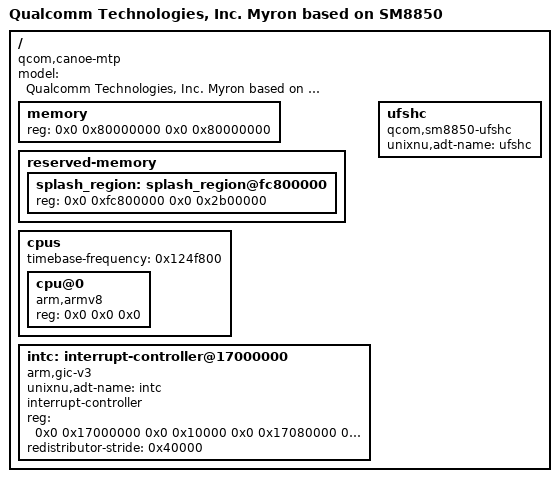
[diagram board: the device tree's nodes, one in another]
// SPDX-License-Identifier: BSD-3-Clause
//
// Redmi K90 Pro Max (myron, SM8850 / Canoe) handoff device tree for UniXNU.
// Generated by work/make_handoff_dts.py -- edit that file, not this one.
//
// This is the curated tree the ADT is built from, not the stock Android DTB
// (dts/myron.dts, kept as the byte-exact address reference). Format 2 exports
// an arm-io child only for a node carrying unixnu,adt-name, so only the nodes
// below reach the kernel.
//
// Values are copied from UniXNU-myron/scripts/make-myron-adt.py, the generator
// that reached SpringBoard on this phone with the iPadOS 17.7.11 image; see the
// docstring of the generator script for where each one came from.

/dts-v1/;

/ {
    model = "Qualcomm Technologies, Inc. Myron based on SM8850";
    compatible = "qcom,canoe-mtp", "qcom,canoe";
    #address-cells = <0x2>;
    #size-cells = <0x2>;

    memory {
        device_type = "memory";
        // First DRAM bank from this unit's boot log; the second
        // (0x880000000 + 0x380000000) is not declared, as upstream.
        reg = <0x0 0x80000000 0x0 0x80000000>;
    };

    // Measured on this unit (myron-observed.json): the ABL splash buffer that
    // the boot image's [[bootimg.dtb_node]] entries address. Values, not guesses.
    reserved-memory {
        #address-cells = <0x2>;
        #size-cells = <0x2>;
        ranges;
        splash_region: splash_region@fc800000 {
            reg = <0x0 0xfc800000 0x0 0x2b00000>;
        };
    };

    cpus {
        #address-cells = <0x2>;
        #size-cells = <0x1>;
        // Copied from the arm,armv8-timer clock-frequency of the stock DTB;
        // XNU reads it from /cpus.
        timebase-frequency = <0x124f800>;
        cpu@0 {
            device_type = "cpu";
            compatible = "arm,armv8";
            reg = <0x0 0x0 0x0>;
        };
    };

    // arm-io child: the ADT name is the child name the kernel looks for.
    intc: interrupt-controller@17000000 {
        unixnu,adt-name = "intc";
        compatible = "arm,gic-v3";
        interrupt-controller;
        #interrupt-cells = <0x3>;
        reg = <0x0 0x17000000 0x0 0x10000 0x0 0x17080000 0x0 0x200000>;
        redistributor-stride = <0x40000>;
    };

    // Class matching only: the host lies below the arm-io window, so there is
    // no reg, and NativeUfs takes its windows from its own constants.
    ufshc {
        unixnu,adt-name = "ufshc";
        compatible = "qcom,sm8850-ufshc", "qcom,sm8550-ufshc";
    };
};
